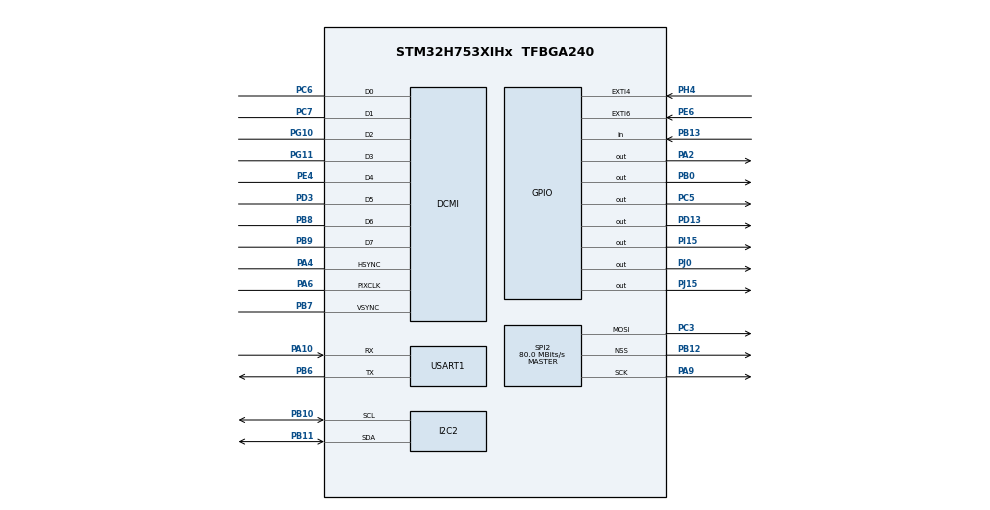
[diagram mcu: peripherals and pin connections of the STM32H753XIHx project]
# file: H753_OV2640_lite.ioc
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DCMI.CaptureRate=DCMI_CR_ALL_FRAME
DCMI.JPEGMode=DCMI_JPEG_DISABLE
DCMI.PCKPolarity=DCMI_PCKPOLARITY_RISING
Dma.DCMI.0.Direction=DMA_PERIPH_TO_MEMORY
Dma.DCMI.0.EventEnable=DISABLE
Dma.DCMI.0.FIFOMode=DMA_FIFOMODE_ENABLE
Dma.DCMI.0.FIFOThreshold=DMA_FIFO_THRESHOLD_FULL
Dma.DCMI.0.Instance=DMA1_Stream0
Dma.DCMI.0.MemBurst=DMA_MBURST_SINGLE
Dma.DCMI.0.MemDataAlignment=DMA_MDATAALIGN_HALFWORD
Dma.DCMI.0.MemInc=DMA_MINC_ENABLE
Dma.DCMI.0.Mode=DMA_CIRCULAR
Dma.DCMI.0.PeriphBurst=DMA_PBURST_SINGLE
Dma.DCMI.0.PeriphDataAlignment=DMA_PDATAALIGN_WORD
Dma.DCMI.0.PeriphInc=DMA_PINC_DISABLE
Dma.DCMI.0.Polarity=HAL_DMAMUX_REQ_GEN_RISING
Dma.DCMI.0.Priority=DMA_PRIORITY_VERY_HIGH
Dma.DCMI.0.RequestNumber=1
Dma.DCMI.0.SignalID=NONE
Dma.DCMI.0.SyncEnable=DISABLE
Dma.DCMI.0.SyncPolarity=HAL_DMAMUX_SYNC_NO_EVENT
Dma.DCMI.0.SyncRequestNumber=1
Dma.DCMI.0.SyncSignalID=NONE
Dma.Request0=DCMI
Dma.Request1=SPI2_TX
Dma.SPI2_TX.1.Direction=DMA_MEMORY_TO_PERIPH
Dma.SPI2_TX.1.EventEnable=DISABLE
Dma.SPI2_TX.1.FIFOMode=DMA_FIFOMODE_DISABLE
Dma.SPI2_TX.1.Instance=DMA1_Stream1
Dma.SPI2_TX.1.MemDataAlignment=DMA_MDATAALIGN_HALFWORD
Dma.SPI2_TX.1.MemInc=DMA_MINC_ENABLE
Dma.SPI2_TX.1.Mode=DMA_NORMAL
Dma.SPI2_TX.1.PeriphDataAlignment=DMA_PDATAALIGN_HALFWORD
Dma.SPI2_TX.1.PeriphInc=DMA_PINC_DISABLE
Dma.SPI2_TX.1.Polarity=HAL_DMAMUX_REQ_GEN_RISING
Dma.SPI2_TX.1.Priority=DMA_PRIORITY_LOW
Dma.SPI2_TX.1.RequestNumber=1
Dma.SPI2_TX.1.SignalID=NONE
Dma.SPI2_TX.1.SyncEnable=DISABLE
Dma.SPI2_TX.1.SyncPolarity=HAL_DMAMUX_SYNC_NO_EVENT
Dma.SPI2_TX.1.SyncRequestNumber=1
Dma.SPI2_TX.1.SyncSignalID=NONE
Mcu.Family=STM32H7
Mcu.Name=STM32H753XIHx
Mcu.Package=TFBGA240
NVIC.DCMI_IRQn=true\:0\:0\:false\:false\:true\:true\:true\:true
NVIC.DMA1_Stream0_IRQn=true\:0\:0\:false\:false\:true\:false\:true\:true
NVIC.DMA1_Stream1_IRQn=true\:0\:0\:false\:false\:true\:false\:true\:true
NVIC.EXTI4_IRQn=true\:0\:0\:false\:false\:true\:true\:true\:true
NVIC.EXTI9_5_IRQn=true\:15\:0\:true\:false\:true\:true\:true\:true
NVIC.PriorityGroup=NVIC_PRIORITYGROUP_4
NVIC.SPI2_IRQn=true\:0\:0\:false\:false\:true\:false\:true\:true
PA0.Signal=SDMMC2_CMD
PA10.Mode=Asynchronous
PA10.Signal=USART1_RX
PA2.PinState=GPIO_PIN_SET
PA2.Signal=GPIO_Output
PA4.Mode=Slave_8_bits_External_Synchro
PA4.Signal=DCMI_HSYNC
PA6.Mode=Slave_8_bits_External_Synchro
PA6.Signal=DCMI_PIXCLK
PA7.Signal=I2S1_SDO
PA9.GPIO_Speed=GPIO_SPEED_FREQ_VERY_HIGH
PA9.Mode=TX_Only_Simplex_Unidirect_Master
PA9.Signal=SPI2_SCK
PB0.Signal=GPIO_Output
PB10.Mode=I2C
PB10.Signal=I2C2_SCL
PB11.Mode=I2C
PB11.Signal=I2C2_SDA
PB12.GPIO_Speed=GPIO_SPEED_FREQ_VERY_HIGH
PB12.Mode=NSS_Signal_Hard_Output
PB12.Signal=SPI2_NSS
PB13.GPIO_PuPd=GPIO_PULLUP
PB13.Signal=GPIO_Input
PB2.Signal=QUADSPI_CLK
PB3\ (JTDO/TRACESWO).Signal=SDMMC2_D2
PB6.Mode=Asynchronous
PB6.Signal=USART1_TX
PB7.Mode=Slave_8_bits_External_Synchro
PB7.Signal=DCMI_VSYNC
PB8.Mode=Slave_8_bits_External_Synchro
PB8.Signal=DCMI_D6
PB9.Mode=Slave_8_bits_External_Synchro
PB9.Signal=DCMI_D7
PC14-OSC32_IN\ (OSC32_IN).Mode=LSE-External-Oscillator
PC14-OSC32_IN\ (OSC32_IN).Signal=RCC_OSC32_IN
PC15-OSC32_OUT\ (OSC32_OUT).Mode=LSE-External-Oscillator
PC15-OSC32_OUT\ (OSC32_OUT).Signal=RCC_OSC32_OUT
PC2.Signal=SPI2_MISO
PC3.GPIO_Speed=GPIO_SPEED_FREQ_VERY_HIGH
PC3.Mode=TX_Only_Simplex_Unidirect_Master
PC3.Signal=SPI2_MOSI
PC5.Signal=GPIO_Output
PC6.Mode=Slave_8_bits_External_Synchro
PC6.Signal=DCMI_D0
PC7.Mode=Slave_8_bits_External_Synchro
PC7.Signal=DCMI_D1
PD13.Signal=GPIO_Output
PD3.Mode=Slave_8_bits_External_Synchro
PD3.Signal=DCMI_D5
PD6.Signal=SDMMC2_CK
PE4.Mode=Slave_8_bits_External_Synchro
PE4.Signal=DCMI_D4
PE6.GPIO_PuPd=GPIO_NOPULL
PE6.Signal=GPXTI6
PF7.Signal=QUADSPI_BK1_IO2
PG10.Mode=Slave_8_bits_External_Synchro
PG10.Signal=DCMI_D2
PG11.Mode=Slave_8_bits_External_Synchro
PG11.Signal=DCMI_D3
PG12.Signal=SPI6_MISO
PG13.Signal=SPI6_SCK
PG14.Signal=SPI6_MOSI
PG6.Signal=QUADSPI_BK1_NCS
PH0-OSC_IN\ (PH0).Mode=HSE-External-Oscillator
PH0-OSC_IN\ (PH0).Signal=RCC_OSC_IN
PH1-OSC_OUT\ (PH1).Mode=HSE-External-Oscillator
PH1-OSC_OUT\ (PH1).Signal=RCC_OSC_OUT
PH4.GPIO_PuPd=GPIO_PULLUP
PH4.Signal=GPXTI4
PH5.Signal=FMC_SDNWE
PH7.Signal=FMC_SDCKE1
PI12.Signal=LTDC_HSYNC
PI13.Signal=LTDC_VSYNC
PI14.Signal=LTDC_CLK
PI15.Signal=GPIO_Output
PJ0.Signal=GPIO_Output
PJ1.Signal=LTDC_R2
PJ10.Signal=LTDC_G3
PJ11.Signal=LTDC_G4
PJ13.Signal=LTDC_B1
PJ15.Signal=GPIO_Output
PJ2.Signal=LTDC_R3
PJ3.Signal=LTDC_R4
PJ4.Signal=LTDC_R5
PJ5.Signal=LTDC_R6
PJ7.Signal=LTDC_G0
PJ8.Signal=LTDC_G1
PJ9.Signal=LTDC_G2
PK0.Signal=LTDC_G5
PK1.Signal=LTDC_G6
PK2.Signal=LTDC_G7
PK3.Signal=LTDC_B4
PK4.Signal=LTDC_B5
PK5.Signal=LTDC_B6
PK6.Signal=LTDC_B7
ProjectManager.HeapSize=0x200
ProjectManager.StackSize=0x400
ProjectManager.TargetToolchain=STM32CubeIDE
RCC.ADCFreq_Value=160000000
RCC.APB1Freq_Value=120000000
RCC.APB2Freq_Value=120000000
RCC.APB3Freq_Value=120000000
RCC.APB4Freq_Value=120000000
RCC.CortexFreq_Value=480000000
RCC.D1PPRE=RCC_APB3_DIV2
RCC.D2PPRE1=RCC_APB1_DIV2
RCC.D2PPRE2=RCC_APB2_DIV2
RCC.D3PPRE=RCC_APB4_DIV2
RCC.DIVM1=5
RCC.DIVM2=5
RCC.DIVN1=192
RCC.DIVN2=160
RCC.DIVN3=208
RCC.DIVP2=5
RCC.DIVQ1=20
RCC.DIVQ2=6
RCC.DIVR2=128
RCC.DIVR3=6
RCC.HCLKFreq_Value=240000000
RCC.HPRE=RCC_HCLK_DIV2
RCC.I2C123CLockSelection=RCC_I2C123CLKSOURCE_HSI
RCC.PLLSourceVirtual=RCC_PLLSOURCE_HSE
RCC.ProductRev=revV
RCC.SPI123CLockSelection=RCC_SPI123CLKSOURCE_PLL2
RCC.SPI6CLockSelection=RCC_SPI6CLKSOURCE_PLL2
RCC.SYSCLKFreq_VALUE=480000000
RCC.SYSCLKSource=RCC_SYSCLKSOURCE_PLLCLK
RCC.USART234578CLockSelection=RCC_USART234578CLKSOURCE_PLL2
RCC.USBFreq_Value=48000000
SH.FMC_SDNWE.0=FMC_SDNWE
SPI2.BaudRatePrescaler=SPI_BAUDRATEPRESCALER_2
SPI2.CalculateBaudRate=80.0 MBits/s
SPI2.DataSize=SPI_DATASIZE_8BIT
SPI2.Direction=SPI_DIRECTION_2LINES_TXONLY
SPI2.MasterInterDataIdleness=SPI_MASTER_INTERDATA_IDLENESS_00CYCLE
SPI2.MasterSSIdleness=SPI_MASTER_SS_IDLENESS_00CYCLE
SPI2.Mode=SPI_MODE_MASTER
SPI2.VirtualNSS=VM_NSSHARD
SPI2.VirtualType=VM_MASTER
USART1.VirtualMode-Asynchronous=VM_ASYNC
board=custom

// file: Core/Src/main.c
/* USER CODE BEGIN Header */
/**
  ******************************************************************************
  * @file           : main.c
  * @brief          : Main program body
  ******************************************************************************
  * @attention
  *
  * Copyright (c) 2023 STMicroelectronics.
  * All rights reserved.
  *
  * This software is licensed under terms that can be found in the LICENSE file
  * in the root directory of this software component.
  * If no LICENSE file comes with this software, it is provided AS-IS.
  *
  ******************************************************************************
  */
/* USER CODE END Header */
#include "main.h"

/* USER CODE BEGIN Includes */
#include "custom/inner_main.h"
/* USER CODE END Includes */

DCMI_HandleTypeDef hdcmi;
DMA_HandleTypeDef hdma_dcmi;

I2C_HandleTypeDef hi2c2;

SPI_HandleTypeDef hspi2;
DMA_HandleTypeDef hdma_spi2_tx;

UART_HandleTypeDef huart1;

void SystemClock_Config(void);
static void MX_GPIO_Init(void);
static void MX_DMA_Init(void);
static void MX_SPI2_Init(void);
static void MX_DCMI_Init(void);
static void MX_USART1_UART_Init(void);
static void MX_I2C2_Init(void);

int main(void)
{

  /* MCU Configuration--------------------------------------------------------*/

  /* Reset of all peripherals, Initializes the Flash interface and the Systick. */
  HAL_Init();

  /* Configure the system clock */
  SystemClock_Config();

  /* Initialize all configured peripherals */
  MX_GPIO_Init();
  MX_DMA_Init();
  MX_SPI2_Init();
  MX_DCMI_Init();
  MX_USART1_UART_Init();
  MX_I2C2_Init();

  /* Infinite loop */
  /* USER CODE BEGIN WHILE */
  myMain();
  while (1)
  {
    /* USER CODE END WHILE */

  }
}

void SystemClock_Config(void)
{
  RCC_OscInitTypeDef RCC_OscInitStruct = {0};
  RCC_ClkInitTypeDef RCC_ClkInitStruct = {0};

  /** Supply configuration update enable
  */
  HAL_PWREx_ConfigSupply(PWR_LDO_SUPPLY);

  /** Configure the main internal regulator output voltage
  */
  __HAL_PWR_VOLTAGESCALING_CONFIG(PWR_REGULATOR_VOLTAGE_SCALE1);

  while(!__HAL_PWR_GET_FLAG(PWR_FLAG_VOSRDY)) {}

  __HAL_RCC_SYSCFG_CLK_ENABLE();
  __HAL_PWR_VOLTAGESCALING_CONFIG(PWR_REGULATOR_VOLTAGE_SCALE0);

  while(!__HAL_PWR_GET_FLAG(PWR_FLAG_VOSRDY)) {}

  /** Initializes the RCC Oscillators according to the specified parameters
  * in the RCC_OscInitTypeDef structure.
  */
  RCC_OscInitStruct.OscillatorType = RCC_OSCILLATORTYPE_HSI|RCC_OSCILLATORTYPE_HSE;
  RCC_OscInitStruct.HSEState = RCC_HSE_ON;
  RCC_OscInitStruct.HSIState = RCC_HSI_DIV1;
  RCC_OscInitStruct.HSICalibrationValue = RCC_HSICALIBRATION_DEFAULT;
  RCC_OscInitStruct.PLL.PLLState = RCC_PLL_ON;
  RCC_OscInitStruct.PLL.PLLSource = RCC_PLLSOURCE_HSE;
  RCC_OscInitStruct.PLL.PLLM = 5;
  RCC_OscInitStruct.PLL.PLLN = 192;
  RCC_OscInitStruct.PLL.PLLP = 2;
  RCC_OscInitStruct.PLL.PLLQ = 20;
  RCC_OscInitStruct.PLL.PLLR = 2;
  RCC_OscInitStruct.PLL.PLLRGE = RCC_PLL1VCIRANGE_2;
  RCC_OscInitStruct.PLL.PLLVCOSEL = RCC_PLL1VCOWIDE;
  RCC_OscInitStruct.PLL.PLLFRACN = 0;
  if (HAL_RCC_OscConfig(&RCC_OscInitStruct) != HAL_OK)
  {
    Error_Handler();
  }

  /** Initializes the CPU, AHB and APB buses clocks
  */
  RCC_ClkInitStruct.ClockType = RCC_CLOCKTYPE_HCLK|RCC_CLOCKTYPE_SYSCLK
                              |RCC_CLOCKTYPE_PCLK1|RCC_CLOCKTYPE_PCLK2
                              |RCC_CLOCKTYPE_D3PCLK1|RCC_CLOCKTYPE_D1PCLK1;
  RCC_ClkInitStruct.SYSCLKSource = RCC_SYSCLKSOURCE_PLLCLK;
  RCC_ClkInitStruct.SYSCLKDivider = RCC_SYSCLK_DIV1;
  RCC_ClkInitStruct.AHBCLKDivider = RCC_HCLK_DIV2;
  RCC_ClkInitStruct.APB3CLKDivider = RCC_APB3_DIV2;
  RCC_ClkInitStruct.APB1CLKDivider = RCC_APB1_DIV2;
  RCC_ClkInitStruct.APB2CLKDivider = RCC_APB2_DIV2;
  RCC_ClkInitStruct.APB4CLKDivider = RCC_APB4_DIV2;

  if (HAL_RCC_ClockConfig(&RCC_ClkInitStruct, FLASH_LATENCY_4) != HAL_OK)
  {
    Error_Handler();
  }
}

static void MX_DCMI_Init(void)
{

  hdcmi.Instance = DCMI;
  hdcmi.Init.SynchroMode = DCMI_SYNCHRO_HARDWARE;
  hdcmi.Init.PCKPolarity = DCMI_PCKPOLARITY_RISING;
  hdcmi.Init.VSPolarity = DCMI_VSPOLARITY_LOW;
  hdcmi.Init.HSPolarity = DCMI_HSPOLARITY_LOW;
  hdcmi.Init.CaptureRate = DCMI_CR_ALL_FRAME;
  hdcmi.Init.ExtendedDataMode = DCMI_EXTEND_DATA_8B;
  hdcmi.Init.JPEGMode = DCMI_JPEG_DISABLE;
  hdcmi.Init.ByteSelectMode = DCMI_BSM_ALL;
  hdcmi.Init.ByteSelectStart = DCMI_OEBS_ODD;
  hdcmi.Init.LineSelectMode = DCMI_LSM_ALL;
  hdcmi.Init.LineSelectStart = DCMI_OELS_ODD;
  if (HAL_DCMI_Init(&hdcmi) != HAL_OK)
  {
    Error_Handler();
  }

}

static void MX_I2C2_Init(void)
{

  hi2c2.Instance = I2C2;
  hi2c2.Init.Timing = 0x10707DBC;
  hi2c2.Init.OwnAddress1 = 0;
  hi2c2.Init.AddressingMode = I2C_ADDRESSINGMODE_7BIT;
  hi2c2.Init.DualAddressMode = I2C_DUALADDRESS_DISABLE;
  hi2c2.Init.OwnAddress2 = 0;
  hi2c2.Init.OwnAddress2Masks = I2C_OA2_NOMASK;
  hi2c2.Init.GeneralCallMode = I2C_GENERALCALL_DISABLE;
  hi2c2.Init.NoStretchMode = I2C_NOSTRETCH_DISABLE;
  if (HAL_I2C_Init(&hi2c2) != HAL_OK)
  {
    Error_Handler();
  }

  /** Configure Analogue filter
  */
  if (HAL_I2CEx_ConfigAnalogFilter(&hi2c2, I2C_ANALOGFILTER_ENABLE) != HAL_OK)
  {
    Error_Handler();
  }

  /** Configure Digital filter
  */
  if (HAL_I2CEx_ConfigDigitalFilter(&hi2c2, 0) != HAL_OK)
  {
    Error_Handler();
  }

}

static void MX_SPI2_Init(void)
{

  /* SPI2 parameter configuration*/
  hspi2.Instance = SPI2;
  hspi2.Init.Mode = SPI_MODE_MASTER;
  hspi2.Init.Direction = SPI_DIRECTION_2LINES_TXONLY;
  hspi2.Init.DataSize = SPI_DATASIZE_8BIT;
  hspi2.Init.CLKPolarity = SPI_POLARITY_LOW;
  hspi2.Init.CLKPhase = SPI_PHASE_1EDGE;
  hspi2.Init.NSS = SPI_NSS_HARD_OUTPUT;
  hspi2.Init.BaudRatePrescaler = SPI_BAUDRATEPRESCALER_2;
  hspi2.Init.FirstBit = SPI_FIRSTBIT_MSB;
  hspi2.Init.TIMode = SPI_TIMODE_DISABLE;
  hspi2.Init.CRCCalculation = SPI_CRCCALCULATION_DISABLE;
  hspi2.Init.CRCPolynomial = 0x0;
  hspi2.Init.NSSPMode = SPI_NSS_PULSE_ENABLE;
  hspi2.Init.NSSPolarity = SPI_NSS_POLARITY_LOW;
  hspi2.Init.FifoThreshold = SPI_FIFO_THRESHOLD_01DATA;
  hspi2.Init.TxCRCInitializationPattern = SPI_CRC_INITIALIZATION_ALL_ZERO_PATTERN;
  hspi2.Init.RxCRCInitializationPattern = SPI_CRC_INITIALIZATION_ALL_ZERO_PATTERN;
  hspi2.Init.MasterSSIdleness = SPI_MASTER_SS_IDLENESS_00CYCLE;
  hspi2.Init.MasterInterDataIdleness = SPI_MASTER_INTERDATA_IDLENESS_00CYCLE;
  hspi2.Init.MasterReceiverAutoSusp = SPI_MASTER_RX_AUTOSUSP_DISABLE;
  hspi2.Init.MasterKeepIOState = SPI_MASTER_KEEP_IO_STATE_DISABLE;
  hspi2.Init.IOSwap = SPI_IO_SWAP_DISABLE;
  if (HAL_SPI_Init(&hspi2) != HAL_OK)
  {
    Error_Handler();
  }

}

static void MX_USART1_UART_Init(void)
{

  huart1.Instance = USART1;
  huart1.Init.BaudRate = 115200;
  huart1.Init.WordLength = UART_WORDLENGTH_8B;
  huart1.Init.StopBits = UART_STOPBITS_1;
  huart1.Init.Parity = UART_PARITY_NONE;
  huart1.Init.Mode = UART_MODE_TX_RX;
  huart1.Init.HwFlowCtl = UART_HWCONTROL_NONE;
  huart1.Init.OverSampling = UART_OVERSAMPLING_16;
  huart1.Init.OneBitSampling = UART_ONE_BIT_SAMPLE_DISABLE;
  huart1.Init.ClockPrescaler = UART_PRESCALER_DIV1;
  huart1.AdvancedInit.AdvFeatureInit = UART_ADVFEATURE_NO_INIT;
  if (HAL_UART_Init(&huart1) != HAL_OK)
  {
    Error_Handler();
  }
  if (HAL_UARTEx_SetTxFifoThreshold(&huart1, UART_TXFIFO_THRESHOLD_1_8) != HAL_OK)
  {
    Error_Handler();
  }
  if (HAL_UARTEx_SetRxFifoThreshold(&huart1, UART_RXFIFO_THRESHOLD_1_8) != HAL_OK)
  {
    Error_Handler();
  }
  if (HAL_UARTEx_DisableFifoMode(&huart1) != HAL_OK)
  {
    Error_Handler();
  }

}

static void MX_DMA_Init(void)
{

  /* DMA controller clock enable */
  __HAL_RCC_DMA1_CLK_ENABLE();

  /* DMA interrupt init */
  /* DMA1_Stream0_IRQn interrupt configuration */
  HAL_NVIC_SetPriority(DMA1_Stream0_IRQn, 0, 0);
  HAL_NVIC_EnableIRQ(DMA1_Stream0_IRQn);
  /* DMA1_Stream1_IRQn interrupt configuration */
  HAL_NVIC_SetPriority(DMA1_Stream1_IRQn, 0, 0);
  HAL_NVIC_EnableIRQ(DMA1_Stream1_IRQn);

}

static void MX_GPIO_Init(void)
{
  GPIO_InitTypeDef GPIO_InitStruct = {0};

  /* GPIO Ports Clock Enable */
  __HAL_RCC_GPIOK_CLK_ENABLE();
  __HAL_RCC_GPIOG_CLK_ENABLE();
  __HAL_RCC_GPIOB_CLK_ENABLE();
  __HAL_RCC_GPIOJ_CLK_ENABLE();
  __HAL_RCC_GPIOD_CLK_ENABLE();
  __HAL_RCC_GPIOC_CLK_ENABLE();
  __HAL_RCC_GPIOE_CLK_ENABLE();
  __HAL_RCC_GPIOA_CLK_ENABLE();
  __HAL_RCC_GPIOI_CLK_ENABLE();
  __HAL_RCC_GPIOH_CLK_ENABLE();
  __HAL_RCC_GPIOF_CLK_ENABLE();

  /*Configure GPIO pin Output Level */
  HAL_GPIO_WritePin(GPIOJ, GPIO_PIN_15|GPIO_PIN_0, GPIO_PIN_RESET);

  /*Configure GPIO pin Output Level */
  HAL_GPIO_WritePin(GPIOA, GPIO_PIN_2, GPIO_PIN_SET);

  /*Configure GPIO pin Output Level */
  HAL_GPIO_WritePin(GPIOI, GPIO_PIN_15, GPIO_PIN_RESET);

  /*Configure GPIO pin Output Level */
  HAL_GPIO_WritePin(GPIOD, GPIO_PIN_13, GPIO_PIN_RESET);

  /*Configure GPIO pin Output Level */
  HAL_GPIO_WritePin(GPIOC, GPIO_PIN_5, GPIO_PIN_RESET);

  /*Configure GPIO pin Output Level */
  HAL_GPIO_WritePin(GPIOB, GPIO_PIN_0, GPIO_PIN_RESET);

  /*Configure GPIO pins : PK5 PK4 PK6 PK3
                           PK2 PK0 PK1 */
  GPIO_InitStruct.Pin = GPIO_PIN_5|GPIO_PIN_4|GPIO_PIN_6|GPIO_PIN_3
                          |GPIO_PIN_2|GPIO_PIN_0|GPIO_PIN_1;
  GPIO_InitStruct.Mode = GPIO_MODE_AF_PP;
  GPIO_InitStruct.Pull = GPIO_NOPULL;
  GPIO_InitStruct.Speed = GPIO_SPEED_FREQ_LOW;
  GPIO_InitStruct.Alternate = GPIO_AF14_LTDC;
  HAL_GPIO_Init(GPIOK, &GPIO_InitStruct);

  /*Configure GPIO pins : PJ15 PJ0 */
  GPIO_InitStruct.Pin = GPIO_PIN_15|GPIO_PIN_0;
  GPIO_InitStruct.Mode = GPIO_MODE_OUTPUT_PP;
  GPIO_InitStruct.Pull = GPIO_NOPULL;
  GPIO_InitStruct.Speed = GPIO_SPEED_FREQ_LOW;
  HAL_GPIO_Init(GPIOJ, &GPIO_InitStruct);

  /*Configure GPIO pin : PD6 */
  GPIO_InitStruct.Pin = GPIO_PIN_6;
  GPIO_InitStruct.Mode = GPIO_MODE_AF_PP;
  GPIO_InitStruct.Pull = GPIO_NOPULL;
  GPIO_InitStruct.Speed = GPIO_SPEED_FREQ_VERY_HIGH;
  GPIO_InitStruct.Alternate = GPIO_AF11_SDIO2;
  HAL_GPIO_Init(GPIOD, &GPIO_InitStruct);

  /*Configure GPIO pin : PB3 */
  GPIO_InitStruct.Pin = GPIO_PIN_3;
  GPIO_InitStruct.Mode = GPIO_MODE_AF_PP;
  GPIO_InitStruct.Pull = GPIO_NOPULL;
  GPIO_InitStruct.Speed = GPIO_SPEED_FREQ_VERY_HIGH;
  GPIO_InitStruct.Alternate = GPIO_AF9_SDIO2;
  HAL_GPIO_Init(GPIOB, &GPIO_InitStruct);

  /*Configure GPIO pins : PG12 PG14 PG13 */
  GPIO_InitStruct.Pin = GPIO_PIN_12|GPIO_PIN_14|GPIO_PIN_13;
  GPIO_InitStruct.Mode = GPIO_MODE_AF_PP;
  GPIO_InitStruct.Pull = GPIO_NOPULL;
  GPIO_InitStruct.Speed = GPIO_SPEED_FREQ_LOW;
  GPIO_InitStruct.Alternate = GPIO_AF5_SPI6;
  HAL_GPIO_Init(GPIOG, &GPIO_InitStruct);

  /*Configure GPIO pin : PE6 */
  GPIO_InitStruct.Pin = GPIO_PIN_6;
  GPIO_InitStruct.Mode = GPIO_MODE_IT_RISING;
  GPIO_InitStruct.Pull = GPIO_NOPULL;
  HAL_GPIO_Init(GPIOE, &GPIO_InitStruct);

  /*Configure GPIO pins : PJ13 PJ11 PJ10 PJ9
                           PJ8 PJ7 PJ1 PJ5
                           PJ2 PJ3 PJ4 */
  GPIO_InitStruct.Pin = GPIO_PIN_13|GPIO_PIN_11|GPIO_PIN_10|GPIO_PIN_9
                          |GPIO_PIN_8|GPIO_PIN_7|GPIO_PIN_1|GPIO_PIN_5
                          |GPIO_PIN_2|GPIO_PIN_3|GPIO_PIN_4;
  GPIO_InitStruct.Mode = GPIO_MODE_AF_PP;
  GPIO_InitStruct.Pull = GPIO_NOPULL;
  GPIO_InitStruct.Speed = GPIO_SPEED_FREQ_LOW;
  GPIO_InitStruct.Alternate = GPIO_AF14_LTDC;
  HAL_GPIO_Init(GPIOJ, &GPIO_InitStruct);

  /*Configure GPIO pin : PG6 */
  GPIO_InitStruct.Pin = GPIO_PIN_6;
  GPIO_InitStruct.Mode = GPIO_MODE_AF_PP;
  GPIO_InitStruct.Pull = GPIO_NOPULL;
  GPIO_InitStruct.Speed = GPIO_SPEED_FREQ_LOW;
  GPIO_InitStruct.Alternate = GPIO_AF10_QUADSPI;
  HAL_GPIO_Init(GPIOG, &GPIO_InitStruct);

  /*Configure GPIO pins : PI12 PI13 PI14 */
  GPIO_InitStruct.Pin = GPIO_PIN_12|GPIO_PIN_13|GPIO_PIN_14;
  GPIO_InitStruct.Mode = GPIO_MODE_AF_PP;
  GPIO_InitStruct.Pull = GPIO_NOPULL;
  GPIO_InitStruct.Speed = GPIO_SPEED_FREQ_LOW;
  GPIO_InitStruct.Alternate = GPIO_AF14_LTDC;
  HAL_GPIO_Init(GPIOI, &GPIO_InitStruct);

  /*Configure GPIO pin : PF7 */
  GPIO_InitStruct.Pin = GPIO_PIN_7;
  GPIO_InitStruct.Mode = GPIO_MODE_AF_PP;
  GPIO_InitStruct.Pull = GPIO_NOPULL;
  GPIO_InitStruct.Speed = GPIO_SPEED_FREQ_LOW;
  GPIO_InitStruct.Alternate = GPIO_AF9_QUADSPI;
  HAL_GPIO_Init(GPIOF, &GPIO_InitStruct);

  /*Configure GPIO pin : PA2 */
  GPIO_InitStruct.Pin = GPIO_PIN_2;
  GPIO_InitStruct.Mode = GPIO_MODE_OUTPUT_PP;
  GPIO_InitStruct.Pull = GPIO_NOPULL;
  GPIO_InitStruct.Speed = GPIO_SPEED_FREQ_LOW;
  HAL_GPIO_Init(GPIOA, &GPIO_InitStruct);

  /*Configure GPIO pin : PA0 */
  GPIO_InitStruct.Pin = GPIO_PIN_0;
  GPIO_InitStruct.Mode = GPIO_MODE_AF_PP;
  GPIO_InitStruct.Pull = GPIO_NOPULL;
  GPIO_InitStruct.Speed = GPIO_SPEED_FREQ_VERY_HIGH;
  GPIO_InitStruct.Alternate = GPIO_AF9_SDIO2;
  HAL_GPIO_Init(GPIOA, &GPIO_InitStruct);

  /*Configure GPIO pin : PH4 */
  GPIO_InitStruct.Pin = GPIO_PIN_4;
  GPIO_InitStruct.Mode = GPIO_MODE_IT_RISING;
  GPIO_InitStruct.Pull = GPIO_PULLUP;
  HAL_GPIO_Init(GPIOH, &GPIO_InitStruct);

  /*Configure GPIO pins : PH5 PH7 */
  GPIO_InitStruct.Pin = GPIO_PIN_5|GPIO_PIN_7;
  GPIO_InitStruct.Mode = GPIO_MODE_AF_PP;
  GPIO_InitStruct.Pull = GPIO_NOPULL;
  GPIO_InitStruct.Speed = GPIO_SPEED_FREQ_VERY_HIGH;
  GPIO_InitStruct.Alternate = GPIO_AF12_FMC;
  HAL_GPIO_Init(GPIOH, &GPIO_InitStruct);

  /*Configure GPIO pin : PI15 */
  GPIO_InitStruct.Pin = GPIO_PIN_15;
  GPIO_InitStruct.Mode = GPIO_MODE_OUTPUT_PP;
  GPIO_InitStruct.Pull = GPIO_NOPULL;
  GPIO_InitStruct.Speed = GPIO_SPEED_FREQ_LOW;
  HAL_GPIO_Init(GPIOI, &GPIO_InitStruct);

  /*Configure GPIO pin : PA7 */
  GPIO_InitStruct.Pin = GPIO_PIN_7;
  GPIO_InitStruct.Mode = GPIO_MODE_AF_PP;
  GPIO_InitStruct.Pull = GPIO_NOPULL;
  GPIO_InitStruct.Speed = GPIO_SPEED_FREQ_LOW;
  GPIO_InitStruct.Alternate = GPIO_AF5_SPI1;
  HAL_GPIO_Init(GPIOA, &GPIO_InitStruct);

  /*Configure GPIO pin : PB2 */
  GPIO_InitStruct.Pin = GPIO_PIN_2;
  GPIO_InitStruct.Mode = GPIO_MODE_AF_PP;
  GPIO_InitStruct.Pull = GPIO_NOPULL;
  GPIO_InitStruct.Speed = GPIO_SPEED_FREQ_LOW;
  GPIO_InitStruct.Alternate = GPIO_AF9_QUADSPI;
  HAL_GPIO_Init(GPIOB, &GPIO_InitStruct);

  /*Configure GPIO pin : PD13 */
  GPIO_InitStruct.Pin = GPIO_PIN_13;
  GPIO_InitStruct.Mode = GPIO_MODE_OUTPUT_PP;
  GPIO_InitStruct.Pull = GPIO_NOPULL;
  GPIO_InitStruct.Speed = GPIO_SPEED_FREQ_LOW;
  HAL_GPIO_Init(GPIOD, &GPIO_InitStruct);

  /*Configure GPIO pin : PC5 */
  GPIO_InitStruct.Pin = GPIO_PIN_5;
  GPIO_InitStruct.Mode = GPIO_MODE_OUTPUT_PP;
  GPIO_InitStruct.Pull = GPIO_NOPULL;
  GPIO_InitStruct.Speed = GPIO_SPEED_FREQ_LOW;
  HAL_GPIO_Init(GPIOC, &GPIO_InitStruct);

  /*Configure GPIO pin : PB0 */
  GPIO_InitStruct.Pin = GPIO_PIN_0;
  GPIO_InitStruct.Mode = GPIO_MODE_OUTPUT_PP;
  GPIO_InitStruct.Pull = GPIO_NOPULL;
  GPIO_InitStruct.Speed = GPIO_SPEED_FREQ_LOW;
  HAL_GPIO_Init(GPIOB, &GPIO_InitStruct);

  /*Configure GPIO pin : PB13 */
  GPIO_InitStruct.Pin = GPIO_PIN_13;
  GPIO_InitStruct.Mode = GPIO_MODE_INPUT;
  GPIO_InitStruct.Pull = GPIO_PULLUP;
  HAL_GPIO_Init(GPIOB, &GPIO_InitStruct);

  /* EXTI interrupt init*/
  HAL_NVIC_SetPriority(EXTI4_IRQn, 0, 0);
  HAL_NVIC_EnableIRQ(EXTI4_IRQn);

  HAL_NVIC_SetPriority(EXTI9_5_IRQn, 15, 0);
  HAL_NVIC_EnableIRQ(EXTI9_5_IRQn);

}

void Error_Handler(void)
{
  __disable_irq();
  while (1)
  {
  }
}
